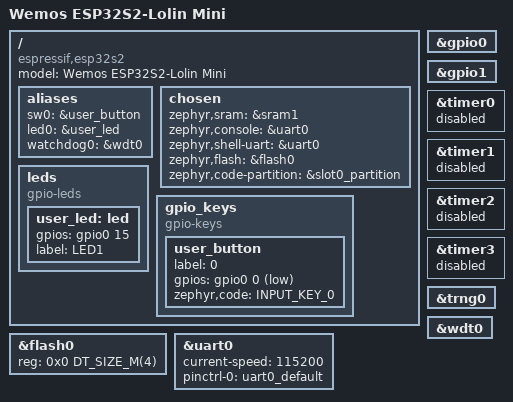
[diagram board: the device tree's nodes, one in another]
/*
 * Copyright (c) 2023 Google, LLC
 *
 * SPDX-License-Identifier: Apache-2.0
 */

/dts-v1/;

#include <espressif/esp32s2/esp32s2.dtsi>
#include <zephyr/dt-bindings/input/input-event-codes.h>
#include "esp32s2_lolin_mini-pinctrl.dtsi"
#include <espressif/partitions_0x1000_default.dtsi>

/ {
	model = "Wemos ESP32S2-Lolin Mini";
	compatible = "espressif,esp32s2";

	aliases {
		sw0 = &user_button;
		led0 = &user_led;
		watchdog0 = &wdt0;
	};

	chosen {
		zephyr,sram = &sram1;
		zephyr,console = &uart0;
		zephyr,shell-uart = &uart0;
		zephyr,flash = &flash0;
		zephyr,code-partition = &slot0_partition;
	};

	leds {
		compatible = "gpio-leds";
		user_led: led {
			gpios =  <&gpio0 15 GPIO_ACTIVE_HIGH>;
			label = "LED1";
		};
	};

	gpio_keys {
		compatible = "gpio-keys";
		user_button: user_button {
			label = "0";
			gpios = <&gpio0 0 (GPIO_PULL_UP | GPIO_ACTIVE_LOW)>;
			zephyr,code = <INPUT_KEY_0>;
		};
	};
};

&flash0 {
	reg = <0x0 DT_SIZE_M(4)>;
};

&uart0 {
	status = "okay";
	current-speed = <115200>;
	pinctrl-0 = <&uart0_default>;
	pinctrl-names = "default";
};

&gpio0 {
	status = "okay";
};

&gpio1 {
	status = "okay";
};

&timer0 {
	status = "disabled";
};

&timer1 {
	status = "disabled";
};

&timer2 {
	status = "disabled";
};

&timer3 {
	status = "disabled";
};

&trng0 {
	status = "okay";
};

&wdt0 {
	status = "okay";
};
